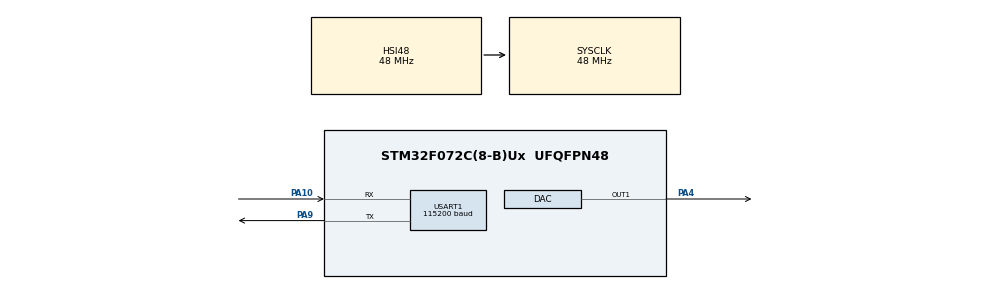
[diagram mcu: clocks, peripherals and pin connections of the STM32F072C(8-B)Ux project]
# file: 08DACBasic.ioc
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Mcu.Family=STM32F0
Mcu.Name=STM32F072C(8-B)Ux
Mcu.Package=UFQFPN48
PA10.Mode=Asynchronous
PA10.Signal=USART1_RX
PA13.Mode=Serial_Wire
PA13.Signal=SYS_SWDIO
PA14.Mode=Serial_Wire
PA14.Signal=SYS_SWCLK
PA4.Signal=COMP_DAC1_group
PA9.Mode=Asynchronous
PA9.Signal=USART1_TX
ProjectManager.HeapSize=0x200
ProjectManager.StackSize=0x400
ProjectManager.TargetToolchain=MDK-ARM V5.32
RCC.SYSCLKFreq_VALUE=48000000
RCC.SYSCLKSource=RCC_SYSCLKSOURCE_HSI48
SH.COMP_DAC1_group.0=DAC_OUT1,DAC_OUT1
USART1.BaudRate=115200
USART1.VirtualMode-Asynchronous=VM_ASYNC
board=custom

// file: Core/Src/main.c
/* USER CODE BEGIN Header */
/**
  ******************************************************************************
  * @file           : main.c
  * @brief          : Main program body
  ******************************************************************************
  * @attention
  *
  * Copyright (c) 2026 STMicroelectronics.
  * All rights reserved.
  *
  * This software is licensed under terms that can be found in the LICENSE file
  * in the root directory of this software component.
  * If no LICENSE file comes with this software, it is provided AS-IS.
  *
  ******************************************************************************
  */
/* USER CODE END Header */
#include "main.h"

/* USER CODE BEGIN Includes */
#include <stdio.h>
/*
 * DAC_OUT1 软件锯齿波：PA4 输出，USART1 PA9 每周期打印一次日志。
 * 12 位右对齐码值理论范围 0..4095，输出约为 VDDA×码值/4095。
 * 输出缓冲器虽已启用，PA4 仍不能直接驱动电机、扬声器等大负载。
 */
/* USER CODE END Includes */

DAC_HandleTypeDef hdac;

UART_HandleTypeDef huart1;

/* USER CODE BEGIN PV */
/* 当前 DAC 码值；以 64 为步进，到 4032 后回到 0。 */
static uint32_t dac_value;
/* USER CODE END PV */

void SystemClock_Config(void);
static void MX_GPIO_Init(void);
static void MX_DAC_Init(void);
static void MX_USART1_UART_Init(void);
/* USER CODE BEGIN PFP */
static void App_Init(void);
static void App_Loop(void);
/* USER CODE END PFP */

/* USER CODE BEGIN 0 */
/** @brief 通过 USART1 输出周期日志，单次阻塞最长 100 ms。 */
int _write(int file,char *ptr,int len){(void)file;if(ptr==NULL||len<=0)return 0;return HAL_UART_Transmit(&huart1,(uint8_t*)ptr,(uint16_t)len,100U)==HAL_OK?len:-1;}
#if defined(__CC_ARM) || defined(__ARMCC_VERSION)
int fputc(int ch, FILE *stream){uint8_t byte=(uint8_t)ch;(void)stream;return HAL_UART_Transmit(&huart1,&byte,1U,100U)==HAL_OK?ch:EOF;}
#endif
/** @brief 启动 DAC 通道 1；失败时进入 Error_Handler() 供断点排查。 */
static void App_Init(void){if(HAL_DAC_Start(&hdac,DAC_CHANNEL_1)!=HAL_OK)Error_Handler();}
/*
 * DAC_ALIGN_12B_R 表示数值放在寄存器低 12 位。0..4032 共 64 个点，
 * 每点约 16 ms，理论周期约 1.024 s、频率约 0.98 Hz。
 * 仅在周期结束时打印，避免逐点串口阻塞改变波形节奏。
 */
static void App_Loop(void){if(HAL_DAC_SetValue(&hdac,DAC_CHANNEL_1,DAC_ALIGN_12B_R,dac_value)!=HAL_OK)Error_Handler();HAL_Delay(16U);if(dac_value>=4032U){dac_value=0U;printf("DAC waveform cycle complete\r\n");}else dac_value+=64U;}
/* USER CODE END 0 */

int main(void)
{

  /* MCU Configuration--------------------------------------------------------*/

  /* Reset of all peripherals, Initializes the Flash interface and the Systick. */
  HAL_Init();

  /* Configure the system clock */
  SystemClock_Config();

  /* Initialize all configured peripherals */
  MX_GPIO_Init();
  MX_DAC_Init();
  MX_USART1_UART_Init();
  /* USER CODE BEGIN 2 */
  App_Init();
  /* USER CODE END 2 */

  /* Infinite loop */
  /* USER CODE BEGIN WHILE */
  while (1)
  {
    App_Loop();
    /* USER CODE END WHILE */

  }
}

void SystemClock_Config(void)
{
  RCC_OscInitTypeDef RCC_OscInitStruct = {0};
  RCC_ClkInitTypeDef RCC_ClkInitStruct = {0};
  RCC_PeriphCLKInitTypeDef PeriphClkInit = {0};

  /** Initializes the RCC Oscillators according to the specified parameters
  * in the RCC_OscInitTypeDef structure.
  */
  RCC_OscInitStruct.OscillatorType = RCC_OSCILLATORTYPE_HSI48;
  RCC_OscInitStruct.HSI48State = RCC_HSI48_ON;
  RCC_OscInitStruct.PLL.PLLState = RCC_PLL_NONE;
  if (HAL_RCC_OscConfig(&RCC_OscInitStruct) != HAL_OK)
  {
    Error_Handler();
  }

  /** Initializes the CPU, AHB and APB buses clocks
  */
  RCC_ClkInitStruct.ClockType = RCC_CLOCKTYPE_HCLK|RCC_CLOCKTYPE_SYSCLK
                              |RCC_CLOCKTYPE_PCLK1;
  RCC_ClkInitStruct.SYSCLKSource = RCC_SYSCLKSOURCE_HSI48;
  RCC_ClkInitStruct.AHBCLKDivider = RCC_SYSCLK_DIV1;
  RCC_ClkInitStruct.APB1CLKDivider = RCC_HCLK_DIV1;

  if (HAL_RCC_ClockConfig(&RCC_ClkInitStruct, FLASH_LATENCY_1) != HAL_OK)
  {
    Error_Handler();
  }
  PeriphClkInit.PeriphClockSelection = RCC_PERIPHCLK_USART1;
  PeriphClkInit.Usart1ClockSelection = RCC_USART1CLKSOURCE_PCLK1;
  if (HAL_RCCEx_PeriphCLKConfig(&PeriphClkInit) != HAL_OK)
  {
    Error_Handler();
  }
}

static void MX_DAC_Init(void)
{

  DAC_ChannelConfTypeDef sConfig = {0};

  /** DAC Initialization
  */
  hdac.Instance = DAC;
  if (HAL_DAC_Init(&hdac) != HAL_OK)
  {
    Error_Handler();
  }

  /** DAC channel OUT1 config
  */
  sConfig.DAC_Trigger = DAC_TRIGGER_NONE;
  sConfig.DAC_OutputBuffer = DAC_OUTPUTBUFFER_ENABLE;
  if (HAL_DAC_ConfigChannel(&hdac, &sConfig, DAC_CHANNEL_1) != HAL_OK)
  {
    Error_Handler();
  }

}

static void MX_USART1_UART_Init(void)
{

  huart1.Instance = USART1;
  huart1.Init.BaudRate = 115200;
  huart1.Init.WordLength = UART_WORDLENGTH_8B;
  huart1.Init.StopBits = UART_STOPBITS_1;
  huart1.Init.Parity = UART_PARITY_NONE;
  huart1.Init.Mode = UART_MODE_TX_RX;
  huart1.Init.HwFlowCtl = UART_HWCONTROL_NONE;
  huart1.Init.OverSampling = UART_OVERSAMPLING_16;
  huart1.Init.OneBitSampling = UART_ONE_BIT_SAMPLE_DISABLE;
  huart1.AdvancedInit.AdvFeatureInit = UART_ADVFEATURE_NO_INIT;
  if (HAL_UART_Init(&huart1) != HAL_OK)
  {
    Error_Handler();
  }

}

static void MX_GPIO_Init(void)
{

  /* GPIO Ports Clock Enable */
  __HAL_RCC_GPIOA_CLK_ENABLE();

}

void Error_Handler(void)
{
  __disable_irq();
  while (1)
  {
  }
}
